AUTOSAR XML (schema 00051)
package /ComponentTypes
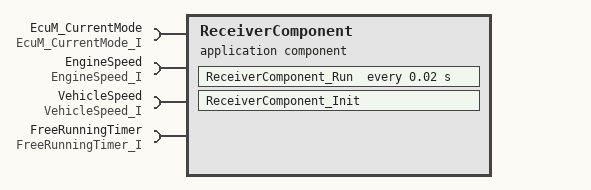
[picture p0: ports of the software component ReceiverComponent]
  application sw component type ReceiverComponent
    4 x require port:
      EcuM_CurrentMode: mode-switch-receiver-com-spec{enhanced-mode-api=false, mode-group=currentMode, supports-asynchronous-mode-switch=false}, required-interface=EcuM_CurrentMode_I
      EngineSpeed: nonqueued-receiver-com-spec{data-element=EngineSpeed, init-value=constant-reference=EngineSpeed_IV}, required-interface=EngineSpeed_I
      VehicleSpeed: nonqueued-receiver-com-spec{data-element=VehicleSpeed, init-value=constant-reference=VehicleSpeed_IV}, required-interface=VehicleSpeed_I
      FreeRunningTimer: required-interface=FreeRunningTimer_I
    behavior ReceiverComponent_InternalBehavior
      swc mode switch event MST_ReceiverComponent_Init: start-on-event=ReceiverComponent_Init, activation=ON-ENTRY, mode=EcuM_CurrentMode.currentMode.RUN
      timing event TMT_ReceiverComponent_Run: start-on-event=ReceiverComponent_Run, period=0.02
      port-api-options:
        enable-take-address=false, indirect-api=false, port=EngineSpeed
        enable-take-address=false, indirect-api=false, port=FreeRunningTimer
        enable-take-address=false, indirect-api=false, port=VehicleSpeed
      runnable ReceiverComponent_Init
      runnable ReceiverComponent_Run
        data-receive-point-by-arguments:
          access REC_EngineSpeed_EngineSpeed: accessed-variable=EngineSpeed.EngineSpeed
          access REC_VehicleSpeed_VehicleSpeed: accessed-variable=VehicleSpeed.VehicleSpeed
        sync call SC_FreeRunningTimer_GetTime: operation=FreeRunningTimer.GetTime, timeout=0
        sync call SC_FreeRunningTimer_IsTimerElapsed: operation=FreeRunningTimer.IsTimerElapsed, timeout=0
  swc implementation ReceiverComponent_Implementation: behavior=ReceiverComponent_InternalBehavior
